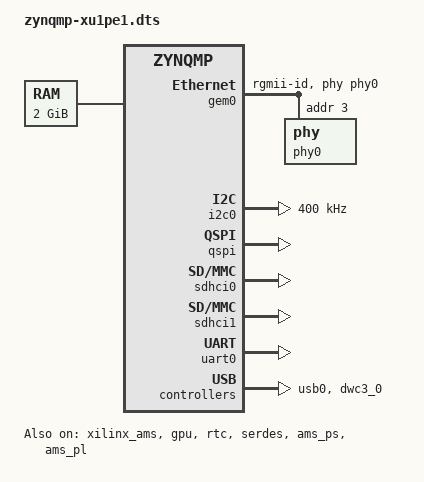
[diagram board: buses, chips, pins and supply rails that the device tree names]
/*
 * CAUTION: This file is automatically generated by Xilinx.
 * Version: XSCT 2018.3
 * Today is: Sat Mar 30 22:24:06 2019
 */


/dts-v1/;
#include "zynqmp-xu1pe1.dtsi"
#include "zynqmp-clk-ccf-xu1pe1.dtsi"

/ {
	chosen {
		bootargs = "earlycon clk_ignore_unused";
		stdout-path = "serial0:115200n8";
	};
	aliases {
		ethernet0 = &gem0;
		i2c0 = &i2c0;
		serial0 = &uart0;
		spi0 = &qspi;
		mmc0 = &sdhci0;
		mmc1 = &sdhci1;
	};
	memory {
		device_type = "memory";
		reg = <0x0 0x0 0x0 0x7ff00000>;
	};
};

&gic {
	num_cpus = <2>;
	num_interrupts = <96>;
};
&lpd_dma_chan1 {
	status = "okay";
};
&lpd_dma_chan2 {
	status = "okay";
};
&lpd_dma_chan3 {
	status = "okay";
};
&lpd_dma_chan4 {
	status = "okay";
};
&lpd_dma_chan5 {
	status = "okay";
};
&lpd_dma_chan6 {
	status = "okay";
};
&lpd_dma_chan7 {
	status = "okay";
};
&lpd_dma_chan8 {
	status = "okay";
};
&xilinx_ams {
	status = "okay";
};
&perf_monitor_ocm {
	xlnx,enable-32bit-filter-id = <0x1>;
	xlnx,enable-advanced = <0x1>;
	xlnx,enable-event-count = <0x1>;
	xlnx,enable-event-log = <0x0>;
	xlnx,enable-profile = <0x0>;
	xlnx,enable-trace = <0x0>;
	xlnx,fifo-axis-depth = <0x20>;
	xlnx,fifo-axis-tdata-width = <0x38>;
	xlnx,fifo-axis-tid-width = <0x1>;
	xlnx,global-count-width = <0x20>;
	xlnx,have-sampled-metric-cnt = <0x1>;
	xlnx,metric-count-scale = <0x1>;
	xlnx,metrics-sample-count-width = <0x20>;
	xlnx,num-monitor-slots = <0x1>;
	xlnx,num-of-counters = <0x3>;
};
&gem0 {
	phy-mode = "rgmii-id";
	phy-handle = <&phy0>;
	status = "okay";
	xlnx,ptp-enet-clock = <0x0>;
	phy0: phy@3 {
		reg = <0x3>;
	};
};
&fpd_dma_chan1 {
	status = "okay";
};
&fpd_dma_chan2 {
	status = "okay";
};
&fpd_dma_chan3 {
	status = "okay";
};
&fpd_dma_chan4 {
	status = "okay";
};
&fpd_dma_chan5 {
	status = "okay";
};
&fpd_dma_chan6 {
	status = "okay";
};
&fpd_dma_chan7 {
	status = "okay";
};
&fpd_dma_chan8 {
	status = "okay";
};
&gpio {
	emio-gpio-width = <32>;
	gpio-mask-high = <0x0>;
	gpio-mask-low = <0x5600>;
	status = "okay";
};
&gpu {
	status = "okay";
};
&i2c0 {
	clock-frequency = <400000>;
	status = "okay";
};
&pinctrl0 {
	status = "okay";
};
&qspi {
	is-dual = <0>;
	num-cs = <1>;
	spi-rx-bus-width = <4>;
	spi-tx-bus-width = <4>;
	status = "okay";
};
&rtc {
	status = "okay";
};
&sdhci0 {
	clock-frequency = <199998001>;
	status = "okay";
	xlnx,mio_bank = <0x0>;
};
&sdhci1 {
	clock-frequency = <49999500>;
	status = "okay";
	xlnx,mio_bank = <0x1>;
};
&serdes {
	status = "okay";
};
&uart0 {
	device_type = "serial";
	port-number = <0>;
	status = "okay";
	u-boot,dm-pre-reloc ;
};
&usb0 {
	status = "okay";
	xlnx,usb-polarity = <0x0>;
	xlnx,usb-reset-mode = <0x0>;
};
&dwc3_0 {
	status = "okay";
};
&ams_ps {
	status = "okay";
};
&ams_pl {
	status = "okay";
};
